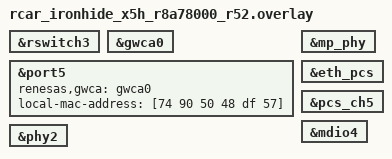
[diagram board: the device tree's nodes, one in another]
/*
 * Copyright (c) 2026 Renesas Electronics Corporation
 *
 * SPDX-License-Identifier: Apache-2.0
 */

&rswitch3 {
	status = "okay";
};

&gwca0 {
	status = "okay";
};

&port5 {
	status = "okay";
	renesas,gwca = <&gwca0>;
	local-mac-address = [74 90 50 48 df 57];
};

&mp_phy {
	status = "okay";
};

&eth_pcs {
	status = "okay";
};

&pcs_ch5 {
	status = "okay";
};

&mdio4 {
	status = "okay";
};

&phy2 {
	status = "okay";
};
